# STM32H743 register map
File version: 2.4
CPU: CM7 r0p1, little endian, MPU, FPU, 4 interrupt priority bits
Registers are 32-bit, read-write, reset 0x0 unless marked. A register's access mark holds for its fields unless they carry their own. Offsets are from the block's base; [hi:lo] are bit positions; 'fields as' and 'values as' point back to an identical list.

## OTG1_HS_GLOBAL — USB 1 OTG 高速
Base 0x40040000
Same registers: OTG2_HS_GLOBAL 0x40080000
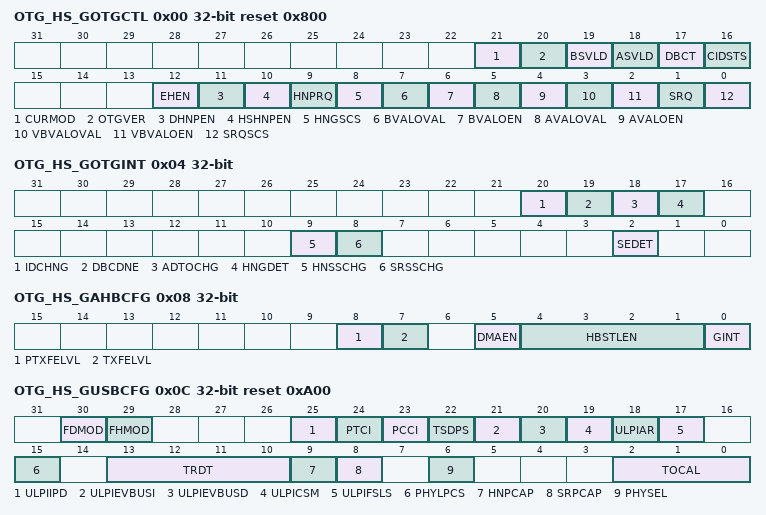
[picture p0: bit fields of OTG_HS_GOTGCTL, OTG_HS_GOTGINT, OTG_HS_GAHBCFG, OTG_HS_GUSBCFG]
0x00 OTG_HS_GOTGCTL access per field reset 0x800 — OTG_HS 控制和状态寄存器
  [21] CURMOD ro — 当前工作模式
  [20] OTGVER rw — OTG 版本
  [19] BSVLD ro — B 会话有效
  [18] ASVLD ro — A 会话有效
  [17] DBCT ro — 长/短去抖时间
  [16] CIDSTS ro — 连接器 ID 状态
  [12] EHEN rw — 嵌入式主机使能
  [11] DHNPEN rw — 设备 HNP 已使能
  [10] HSHNPEN rw — 主机设置 HNP 使能
  [9] HNPRQ rw — HNP 请求
  [8] HNGSCS ro — 主机协商成功
  [7] BVALOVAL rw — B 设备会话有效覆写值
  [6] BVALOEN rw — B 设备会话有效覆写使能
  [5] AVALOVAL rw — A 设备会话有效覆写值
  [4] AVALOEN rw — A 设备会话有效覆写使能
  [3] VBVALOVAL rw — VBUS 有效覆写值
  [2] VBVALOEN rw — VBUS 有效覆写使能
  [1] SRQ rw — 会话请求
  [0] SRQSCS ro — 会话请求成功
0x04 OTG_HS_GOTGINT — OTG_HS 中断寄存器
  [20] IDCHNG — ID 输入引脚变化
  [19] DBCDNE — 去抖完成
  [18] ADTOCHG — A 设备超时变化
  [17] HNGDET — 检测到主机协商
  [9] HNSSCHG — 主机协商成功状态变化
  [8] SRSSCHG — 会话请求成功状态变化
  [2] SEDET — 检测到会话结束
0x08 OTG_HS_GAHBCFG — OTG_HS AHB 配置寄存器
  [8] PTXFELVL — 周期性 TxFIFO 空电平
  [7] TXFELVL — TxFIFO 空电平
  [5] DMAEN — DMA 使能
  [4:1] HBSTLEN — 突发长度/类型
  [0] GINT — 全局中断屏蔽
0x0C OTG_HS_GUSBCFG access per field reset 0xA00 — OTG_HS USB 配置寄存器
  [30] FDMOD rw — 强制外设模式
  [29] FHMOD rw — 强制主机模式
  [25] ULPIIPD rw — ULPI 接口保护禁用
  [24] PTCI rw — 指示器直通
  [23] PCCI rw — 指示器补码
  [22] TSDPS rw — TermSel D 线脉冲选择
  [21] ULPIEVBUSI rw — ULPI 外部 VBUS 指示
  [20] ULPIEVBUSD rw — ULPI 外部 VBUS 驱动
  [19] ULPICSM rw — ULPI 时钟暂停
  [18] ULPIAR rw — ULPI 自动恢复
  [17] ULPIFSLS rw — ULPI 全速/低速选择
  [15] PHYLPCS rw — PHY 低功耗时钟选择
  [13:10] TRDT rw — USB 周转时间
  [9] HNPCAP rw — 支持 HNP
  [8] SRPCAP rw — 支持 SRP
  [6] PHYSEL wo — USB 2.0 高速 ULPI PHY 或 USB 1.1 全速串行收发器选择
  [2:0] TOCAL rw — 全速超时校准
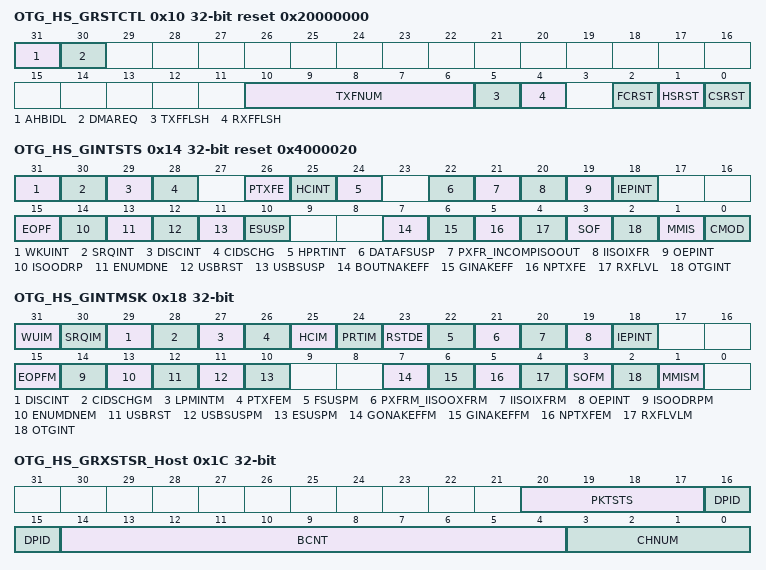
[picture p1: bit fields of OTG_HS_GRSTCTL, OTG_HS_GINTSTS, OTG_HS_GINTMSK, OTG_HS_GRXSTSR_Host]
0x10 OTG_HS_GRSTCTL access per field reset 0x20000000 — OTG_HS 复位寄存器
  [31] AHBIDL ro — AHB 主机空闲
  [30] DMAREQ ro — DMA 请求信号已使能（USB OTG HS）
  [10:6] TXFNUM rw — TxFIFO 编号
  [5] TXFFLSH rw — TxFIFO 刷新
  [4] RXFFLSH rw — RxFIFO 刷新
  [2] FCRST rw — 主机帧计数器复位
  [1] HSRST rw — HCLK 软复位
  [0] CSRST rw — 内核软复位
0x14 OTG_HS_GINTSTS access per field reset 0x4000020 — OTG_HS 内核中断寄存器
  [31] WKUINT rw — 恢复/远程唤醒检测中断
  [30] SRQINT rw — 会话请求/新会话检测中断
  [29] DISCINT rw — 检测到断开连接中断
  [28] CIDSCHG rw — 连接器 ID 状态变化
  [26] PTXFE ro — 周期性 TxFIFO 空
  [25] HCINT ro — 主机通道中断
  [24] HPRTINT ro — 主机端口中断
  [22] DATAFSUSP rw — 数据获取已暂停
  [21] PXFR_INCOMPISOOUT rw — 周期性传输未完成
  [20] IISOIXFR rw — 同步 IN 传输未完成
  [19] OEPINT ro — OUT 端点中断
  [18] IEPINT ro — IN 端点中断
  [15] EOPF rw — 周期性帧结束中断
  [14] ISOODRP rw — 同步 OUT 包丢弃中断
  [13] ENUMDNE rw — 枚举完成
  [12] USBRST rw — USB 复位
  [11] USBSUSP rw — USB 挂起
  [10] ESUSP rw — 提前挂起
  [7] BOUTNAKEFF ro — 全局 OUT NAK 生效
  [6] GINAKEFF ro — 全局 IN 非周期性 NAK 生效
  [5] NPTXFE ro — 非周期性 TxFIFO 空
  [4] RXFLVL ro — RxFIFO 非空
  [3] SOF rw — 帧起始
  [2] OTGINT ro — OTG 中断
  [1] MMIS rw — 模式不匹配中断
  [0] CMOD ro — 当前工作模式
0x18 OTG_HS_GINTMSK access per field — OTG_HS 中断屏蔽寄存器
  [31] WUIM rw — 恢复/远程唤醒检测中断屏蔽
  [30] SRQIM rw — 会话请求/新会话检测中断屏蔽
  [29] DISCINT rw — 断开连接检测中断屏蔽
  [28] CIDSCHGM rw — 连接器 ID 状态变化中断屏蔽
  [27] LPMINTM rw — LPM 中断屏蔽
  [26] PTXFEM rw — 周期性 TxFIFO 空中断屏蔽
  [25] HCIM rw — 主机通道中断屏蔽
  [24] PRTIM ro — 主机端口中断屏蔽
  [23] RSTDE rw — 复位检测中断屏蔽
  [22] FSUSPM rw — 数据获取暂停中断屏蔽
  [21] PXFRM_IISOOXFRM rw — 周期性传输未完成中断屏蔽
  [20] IISOIXFRM rw — 同步 IN 传输未完成中断屏蔽
  [19] OEPINT rw — OUT 端点中断屏蔽
  [18] IEPINT rw — IN 端点中断屏蔽
  [15] EOPFM rw — 周期性帧结束中断屏蔽
  [14] ISOODRPM rw — 同步 OUT 包丢弃中断屏蔽
  [13] ENUMDNEM rw — 枚举完成中断屏蔽
  [12] USBRST rw — USB 复位中断屏蔽
  [11] USBSUSPM rw — USB 挂起中断屏蔽
  [10] ESUSPM rw — 提前挂起中断屏蔽
  [7] GONAKEFFM rw — 全局 OUT NAK 生效中断屏蔽
  [6] GINAKEFFM rw — 全局非周期性 IN NAK 生效中断屏蔽
  [5] NPTXFEM rw — 非周期性 TxFIFO 空中断屏蔽
  [4] RXFLVLM rw — 接收 FIFO 非空中断屏蔽
  [3] SOFM rw — 帧起始中断屏蔽
  [2] OTGINT rw — OTG 中断屏蔽
  [1] MMISM rw — 模式不匹配中断屏蔽
0x1C OTG_HS_GRXSTSR_Host ro — OTG_HS 接收状态调试读取寄存器（主机模式）
  [20:17] PKTSTS — 包状态
  [16:15] DPID — 数据 PID
  [14:4] BCNT — 字节计数
  [3:0] CHNUM — 通道编号
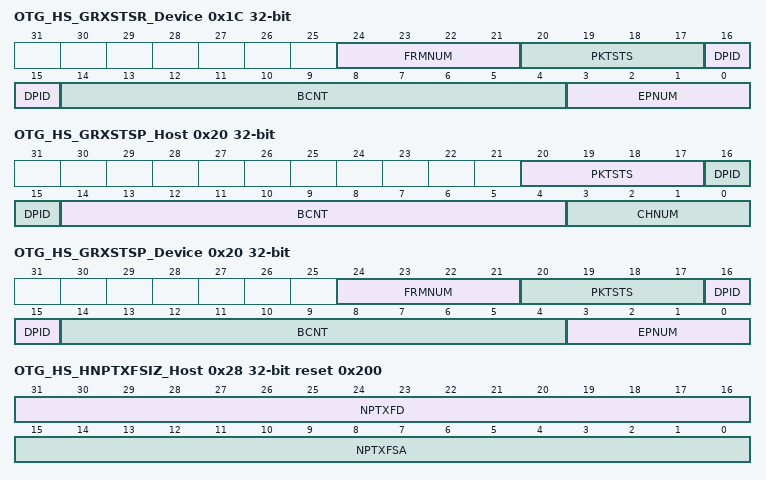
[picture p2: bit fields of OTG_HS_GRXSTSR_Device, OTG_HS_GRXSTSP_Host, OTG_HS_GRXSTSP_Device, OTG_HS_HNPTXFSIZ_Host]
0x1C OTG_HS_GRXSTSR_Device ro (alternate view of OTG_HS_GRXSTSR_Host) — OTG_HS 接收状态调试读取寄存器（外设模式）
  [24:21] FRMNUM — 帧编号
  [20:17] PKTSTS — 包状态
  [16:15] DPID — 数据 PID
  [14:4] BCNT — 字节计数
  [3:0] EPNUM — 端点编号
0x20 OTG_HS_GRXSTSP_Host ro — OTG_HS 状态读取并弹出寄存器（主机模式）
  fields as OTG_HS_GRXSTSR_Host
0x20 OTG_HS_GRXSTSP_Device ro (alternate view of OTG_HS_GRXSTSP_Host) — OTG_HS 状态读取并弹出寄存器（外设模式）
  fields as OTG_HS_GRXSTSR_Device
0x24 OTG_HS_GRXFSIZ reset 0x200 — OTG_HS 接收 FIFO 大小寄存器
  [15:0] RXFD — RxFIFO 深度
0x28 OTG_HS_HNPTXFSIZ_Host reset 0x200 — OTG_HS 非周期性发送 FIFO 大小寄存器（主机模式）
  [31:16] NPTXFD — 非周期性 TxFIFO 深度
  [15:0] NPTXFSA — 非周期性发送 RAM 起始地址
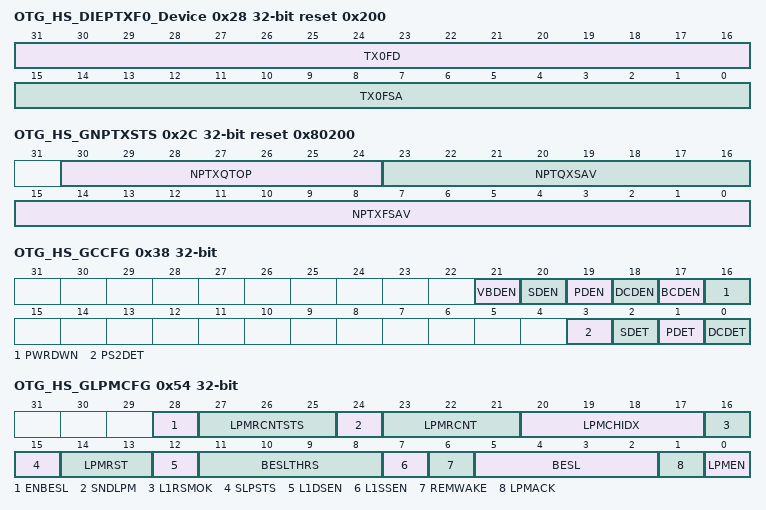
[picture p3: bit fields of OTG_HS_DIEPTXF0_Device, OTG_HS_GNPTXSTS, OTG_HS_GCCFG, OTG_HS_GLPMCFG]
0x28 OTG_HS_DIEPTXF0_Device reset 0x200 (alternate view of OTG_HS_HNPTXFSIZ_Host) — 端点 0 发送 FIFO 大小（外设模式）
  [31:16] TX0FD — 端点 0 TxFIFO 深度
  [15:0] TX0FSA — 端点 0 发送 RAM 起始地址
0x2C OTG_HS_GNPTXSTS ro reset 0x80200 — OTG_HS 非周期性发送 FIFO/队列状态寄存器
  [30:24] NPTXQTOP — 非周期性发送请求队列顶部
  [23:16] NPTQXSAV — 非周期性发送请求队列可用空间
  [15:0] NPTXFSAV — 非周期性 TxFIFO 可用空间
0x38 OTG_HS_GCCFG — OTG_HS 通用内核配置寄存器
  [21] VBDEN — USB VBUS 检测使能
  [20] SDEN — 次级检测（SD）模式使能
  [19] PDEN — 主检测（PD）模式使能
  [18] DCDEN — 数据接触检测（DCD）模式使能
  [17] BCDEN — 电池充电检测器（BCD）使能
  [16] PWRDWN — 断电
  [3] PS2DET — DM 上拉检测状态
  [2] SDET — 次级检测（SD）状态
  [1] PDET — 主检测（PD）状态
  [0] DCDET — 数据接触检测（DCD）状态
0x3C OTG_HS_CID reset 0x1200 — OTG_HS 内核 ID 寄存器
  [31:0] PRODUCT_ID — 产品 ID 字段
0x54 OTG_HS_GLPMCFG access per field — OTG 内核 LPM 配置寄存器
  [28] ENBESL rw — 使能尽力服务延迟
  [27:25] LPMRCNTSTS ro — LPM 重试计数状态
  [24] SNDLPM rw — 发送 LPM 事务
  [23:21] LPMRCNT rw — LPM 重试计数
  [20:17] LPMCHIDX rw — LPM 通道索引
  [16] L1RSMOK ro — 睡眠状态恢复正常
  [15] SLPSTS ro — 端口睡眠状态
  [14:13] LPMRST ro — LPM 响应
  [12] L1DSEN rw — L1 深度睡眠使能
  [11:8] BESLTHRS rw — BESL 阈值
  [7] L1SSEN rw — L1 浅睡眠使能
  [6] REMWAKE ro — bRemoteWake 值
  [5:2] BESL ro — 尽力服务延迟
  [1] LPMACK rw — LPM 令牌应答使能
  [0] LPMEN rw — LPM 支持使能
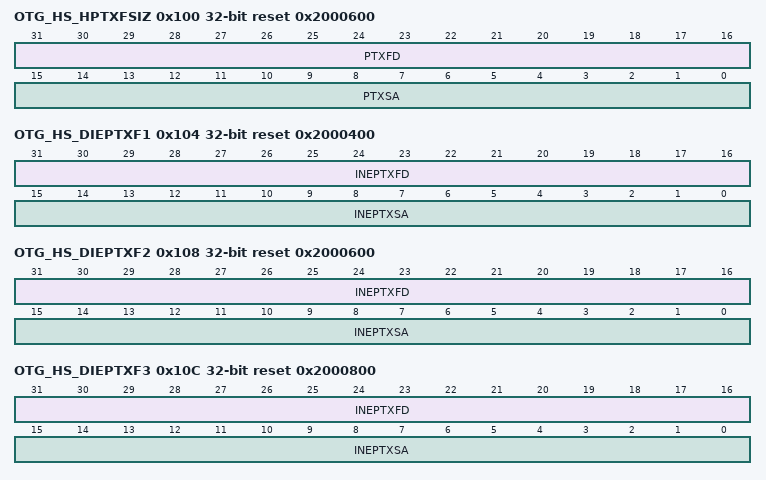
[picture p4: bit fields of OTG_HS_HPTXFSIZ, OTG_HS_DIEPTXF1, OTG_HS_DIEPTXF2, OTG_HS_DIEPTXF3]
0x100 OTG_HS_HPTXFSIZ reset 0x2000600 — OTG_HS 主机周期性发送 FIFO 大小寄存器
  [31:16] PTXFD — 主机周期性 TxFIFO 深度
  [15:0] PTXSA — 主机周期性 TxFIFO 起始地址
0x104 OTG_HS_DIEPTXF1 reset 0x2000400 — OTG_HS 设备 IN 端点发送 FIFO 大小寄存器
  [31:16] INEPTXFD — IN 端点 TxFIFO 深度
  [15:0] INEPTXSA — IN 端点 FIFOx 发送 RAM 起始地址
0x108 OTG_HS_DIEPTXF2 reset 0x2000600 — OTG_HS 设备 IN 端点发送 FIFO 大小寄存器
  fields as OTG_HS_DIEPTXF1
0x10C OTG_HS_DIEPTXF3 reset 0x2000800 — OTG_HS 设备 IN 端点发送 FIFO 大小寄存器
  fields as OTG_HS_DIEPTXF1
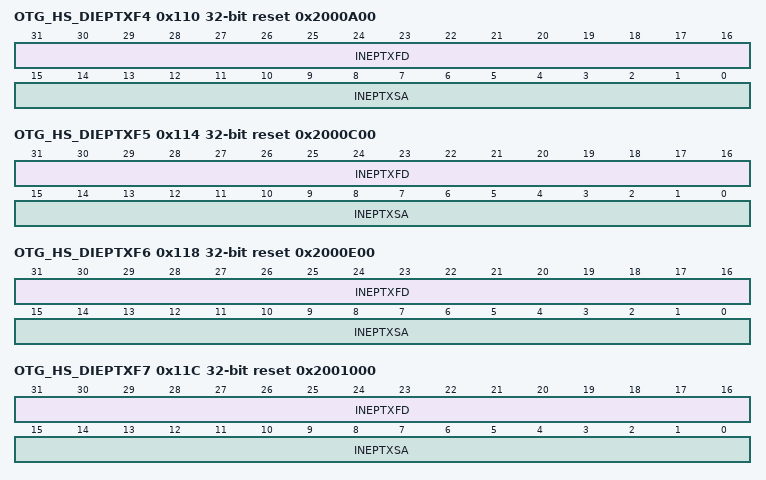
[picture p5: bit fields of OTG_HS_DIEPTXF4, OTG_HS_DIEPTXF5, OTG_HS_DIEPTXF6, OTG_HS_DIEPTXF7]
0x110 OTG_HS_DIEPTXF4 reset 0x2000A00 — OTG_HS 设备 IN 端点发送 FIFO 大小寄存器
  fields as OTG_HS_DIEPTXF1
0x114 OTG_HS_DIEPTXF5 reset 0x2000C00 — OTG_HS 设备 IN 端点发送 FIFO 大小寄存器
  fields as OTG_HS_DIEPTXF1
0x118 OTG_HS_DIEPTXF6 reset 0x2000E00 — OTG_HS 设备 IN 端点发送 FIFO 大小寄存器
  fields as OTG_HS_DIEPTXF1
0x11C OTG_HS_DIEPTXF7 reset 0x2001000 — OTG_HS 设备 IN 端点发送 FIFO 大小寄存器
  fields as OTG_HS_DIEPTXF1
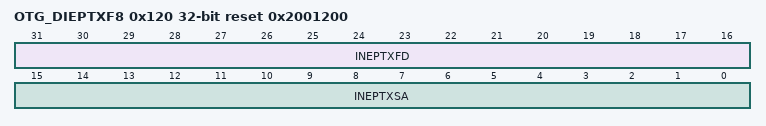
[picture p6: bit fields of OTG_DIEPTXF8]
0x120 OTG_DIEPTXF8 reset 0x2001200
  [31:16] INEPTXFD — IN 端点 TxFIFO 深度。该值以 32 位字为单位，最小值为 16。
  [15:0] INEPTXSA — IN 端点 FIFOx 发送 RAM 起始地址。该字段包含 IN 端点发送 FIFOx 的内存起始地址，地址必须按 32 位内存位置对齐。
